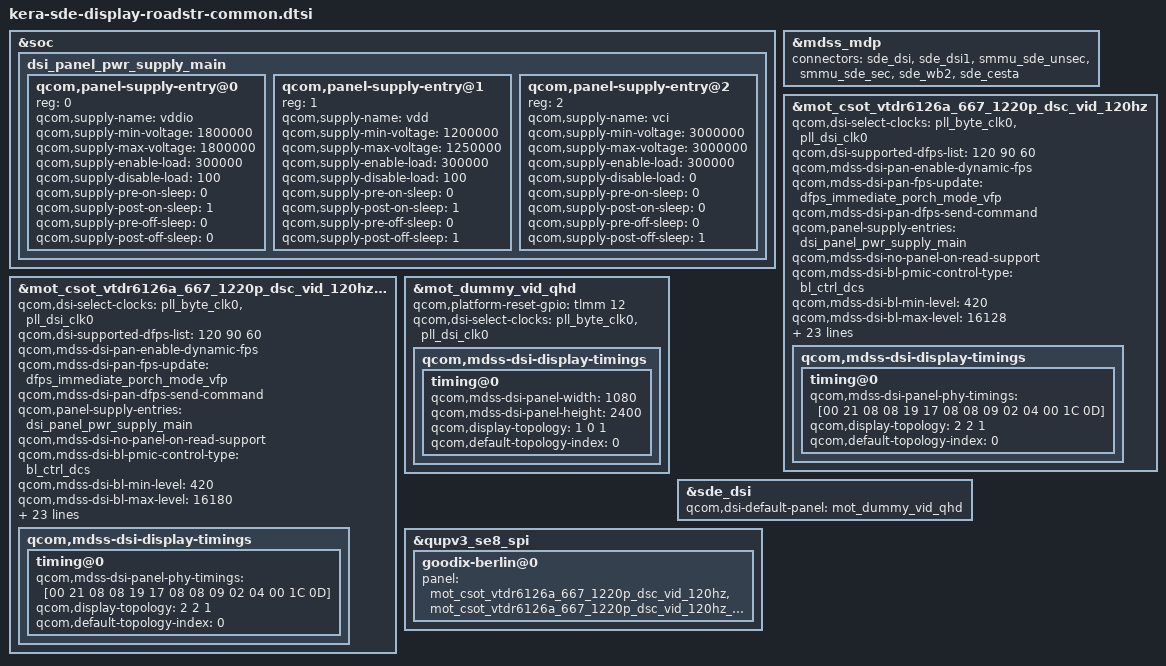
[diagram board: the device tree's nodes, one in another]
// SPDX-License-Identifier: BSD-3-Clause
/*
 * Copyright (c) 2023-2024, Qualcomm Innovation Center, Inc. All rights reserved.
 */

#include "kera-sde.dtsi"
#include "kera-sde-display.dtsi"
#include "dsi-panel-mot-dummy-qhd-video.dtsi"
#include "dsi-panel-mot-csot-vtdr6126a-667-1220x2712-dsc-video-120hz-common.dtsi"
#include "dsi-panel-mot-csot-vtdr6126a-667-1220x2712-dsc-video-120hz-common-lhbm.dtsi"
#include "dsi-panel-mot-csot-vtdr6126a-667-1220x2712-dsc-video-120hz-common-v0.dtsi"
#include "dsi-panel-mot-csot-vtdr6126a-667-1220x2712-dsc-video-120hz-common-lhbm-v0.dtsi"

&soc {
	dsi_panel_pwr_supply_main: dsi_panel_pwr_supply_main {
		#address-cells = <1>;
		#size-cells = <0>;

	qcom,panel-supply-entry@0 {
		reg = <0>;
		qcom,supply-name = "vddio";
		qcom,supply-min-voltage = <1800000>;
		qcom,supply-max-voltage = <1800000>;
		qcom,supply-enable-load = <300000>;
		qcom,supply-disable-load = <100>;
		qcom,supply-pre-on-sleep = <0>;
		qcom,supply-post-on-sleep = <1>;
		qcom,supply-pre-off-sleep = <0>;
		qcom,supply-post-off-sleep = <0>;
        };
	qcom,panel-supply-entry@1 {
		reg = <1>;
		qcom,supply-name = "vdd";
		qcom,supply-min-voltage = <1200000>;
		qcom,supply-max-voltage = <1250000>;
		qcom,supply-enable-load = <300000>;
		qcom,supply-disable-load = <100>;
		qcom,supply-pre-on-sleep = <0>;
		qcom,supply-post-on-sleep = <1>;
		qcom,supply-pre-off-sleep = <0>;
		qcom,supply-post-off-sleep = <1>;
        };

        qcom,panel-supply-entry@2 {
		reg = <2>;
		qcom,supply-name = "vci";
		qcom,supply-min-voltage = <3000000>;
		qcom,supply-max-voltage = <3000000>;
		qcom,supply-enable-load = <300000>;
		qcom,supply-disable-load = <0>;
		qcom,supply-pre-on-sleep = <0>;
		qcom,supply-post-on-sleep = <0>;
		qcom,supply-pre-off-sleep = <0>;
		qcom,supply-post-off-sleep = <1>;
        };
	};
};

&mdss_mdp {
	connectors = <&sde_dsi &sde_dsi1 &smmu_sde_unsec &smmu_sde_sec &sde_wb2 &sde_cesta>;
};


&mot_csot_vtdr6126a_667_1220p_dsc_vid_120hz {
	qcom,dsi-select-clocks = "pll_byte_clk0", "pll_dsi_clk0";

	qcom,dsi-supported-dfps-list = <120 90 60>;
	qcom,mdss-dsi-pan-enable-dynamic-fps;
	qcom,mdss-dsi-pan-fps-update = "dfps_immediate_porch_mode_vfp";
	qcom,mdss-dsi-pan-dfps-send-command;

	//qcom,dsi-dyn-clk-enable;

	qcom,panel-supply-entries = <&dsi_panel_pwr_supply_main>;
	qcom,mdss-dsi-no-panel-on-read-support;
	qcom,mdss-dsi-bl-pmic-control-type = "bl_ctrl_dcs";
	qcom,mdss-dsi-bl-min-level = <420>;//
	qcom,mdss-dsi-bl-max-level = <16128>;
	qcom,mdss-dsi-bl-default-level = <8064>;
	qcom,mdss-brightness-max-level = <16128>;
	qcom,platform-reset-gpio = <&tlmm 12 0>;
	qcom,bl-dsc-cmd-state = "dsi_hs_mode";
	qcom,mdss-dsi-bl-inverted-dbv;
	qcom,mdss-dsi-bl-is-exponent;

	qcom,mdss-dsi-panel-hdr-enabled;
	qcom,mdss-dsi-panel-hdr-color-primaries = <15600 16450 34000
	        16000 13250 34500 7500 3000>;
	qcom,mdss-dsi-panel-peak-brightness = <20000000>;
	qcom,mdss-dsi-panel-blackness-level = <1>;

	qcom,mdss-dsi-panel-status-check-mode = "reg_read";
	qcom,mdss-dsi-panel-status-command = [06 01 00 01 00 00 01 66];
	qcom,mdss-dsi-panel-status-command-state = "dsi_lp_mode";
	qcom,mdss-dsi-panel-status-value = <0 0 0>;
	qcom,mdss-dsi-panel-status-read-length = <3>;
	//qcom,esd-check-enabled;

	qcom,cellid-read-enabled;//
	qcom,mdss-dsi-panel-cellid-read-length = <23>;
	qcom,mdss-dsi-panel-cellid-command = [06 01 00 01 00 00 01 5A];

	qcom,mdss-dsi-display-timings {
		       timing@0 {
		               //qcom,mdss-dsi-panel-clockrate = <1095000000>;
		               qcom,mdss-dsi-panel-phy-timings = [00 21 08 08 19 17 08
		                       08 09 02 04 00 1C 0D];
		               qcom,display-topology = <2 2 1>;
		               qcom,default-topology-index = <0>;
		       };
	       };
};

&mot_csot_vtdr6126a_667_1220p_dsc_vid_120hz_v0 {
	qcom,dsi-select-clocks = "pll_byte_clk0", "pll_dsi_clk0";

	qcom,dsi-supported-dfps-list = <120 90 60>;
	qcom,mdss-dsi-pan-enable-dynamic-fps;
	qcom,mdss-dsi-pan-fps-update = "dfps_immediate_porch_mode_vfp";
	qcom,mdss-dsi-pan-dfps-send-command;

	//qcom,dsi-dyn-clk-enable;

	qcom,panel-supply-entries = <&dsi_panel_pwr_supply_main>;
	qcom,mdss-dsi-no-panel-on-read-support;
	qcom,mdss-dsi-bl-pmic-control-type = "bl_ctrl_dcs";
	qcom,mdss-dsi-bl-min-level = <420>;//
	qcom,mdss-dsi-bl-max-level = <16180>;
	qcom,mdss-dsi-bl-default-level = <8064>;
	qcom,mdss-brightness-max-level = <16180>;
	qcom,platform-reset-gpio = <&tlmm 12 0>;
	qcom,bl-dsc-cmd-state = "dsi_hs_mode";
	qcom,mdss-dsi-bl-inverted-dbv;
	qcom,mdss-dsi-bl-is-exponent;

	qcom,mdss-dsi-panel-hdr-enabled;
	qcom,mdss-dsi-panel-hdr-color-primaries = <15600 16450 34000
	        16000 13250 34500 7500 3000>;
	qcom,mdss-dsi-panel-peak-brightness = <20000000>;
	qcom,mdss-dsi-panel-blackness-level = <1>;

	qcom,mdss-dsi-panel-status-check-mode = "reg_read";
	qcom,mdss-dsi-panel-status-command = [06 01 00 01 00 00 01 66];
	qcom,mdss-dsi-panel-status-command-state = "dsi_lp_mode";
	qcom,mdss-dsi-panel-status-value = <0 0 0>;
	qcom,mdss-dsi-panel-status-read-length = <3>;
	//qcom,esd-check-enabled;

	qcom,cellid-read-enabled;//
	qcom,mdss-dsi-panel-cellid-read-length = <23>;
	qcom,mdss-dsi-panel-cellid-command = [06 01 00 01 00 00 01 5A];

	qcom,mdss-dsi-display-timings {
		       timing@0 {
		               //qcom,mdss-dsi-panel-clockrate = <1095000000>;
		               qcom,mdss-dsi-panel-phy-timings = [00 21 08 08 19 17 08
		                       08 09 02 04 00 1C 0D];
		               qcom,display-topology = <2 2 1>;
		               qcom,default-topology-index = <0>;
		       };
	       };
};


&mot_dummy_vid_qhd {
	qcom,mdss-dsi-display-timings {
		timing@0{
			qcom,mdss-dsi-panel-width = <1080>;
			qcom,mdss-dsi-panel-height = <2400>;
		};
	};
};

&mot_dummy_vid_qhd {
	qcom,platform-reset-gpio = <&tlmm 12 0>;

	qcom,dsi-select-clocks = "pll_byte_clk0", "pll_dsi_clk0";
	qcom,mdss-dsi-display-timings {
		timing@0 {
			qcom,display-topology = <1 0 1>;
			qcom,default-topology-index = <0>;
		};
	};
};

&sde_dsi {
	qcom,dsi-default-panel = <&mot_dummy_vid_qhd>;
};


&qupv3_se8_spi {
	goodix-berlin@0 {
		panel = <&mot_csot_vtdr6126a_667_1220p_dsc_vid_120hz
                        &mot_csot_vtdr6126a_667_1220p_dsc_vid_120hz_v0>;
	};
};
